# liliumSOC1_sysctrl register map
Vendor: Nordic Semiconductor; Series: liliumSOC1; File version: 1
Registers are 32-bit, read-write, reset 0x0 unless marked. A register's access mark holds for its fields unless they carry their own. Offsets are from the block's base; [hi:lo] are bit positions; lines under a group give offsets from that group; {n}, {i} and the like mark numbered series; 'fields as' and 'values as' point back to an identical list.

## OSCRFR_S — OSCRFR peripheral
Base 0x5F96B000
0x400 STATUS ro
  [0] MODE — Current oscillator mode
    0=Normal mode; 1=Bypass mode
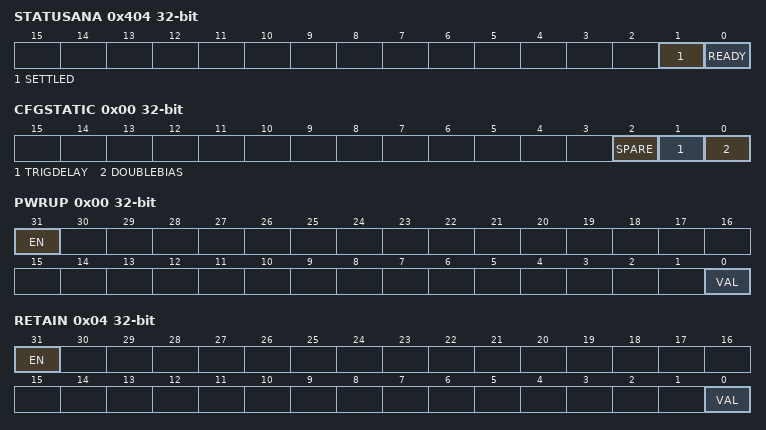
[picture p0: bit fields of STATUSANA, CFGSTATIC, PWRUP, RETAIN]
0x404 STATUSANA ro — Status of analog module output signals
  [1] SETTLED — Current value of the SETTLED signal from the analog module
  [0] READY — Current value of the READY signal from the analog module
0x410 CONFIG group — Unspecified
  0x00 CFGSTATIC — OSCRFR static CFG configuration
    [2] SPARE
    [1] TRIGDELAY — Increase TRIG signal delay
      0=Disabled; 1=Enabled
    [0] DOUBLEBIAS — Enable double bias
      0=Disabled; 1=Enabled
0x440 TRIM group — Unspecified
  0x00 OSC — Oscillation period trimming
    [2:0] VAL — Oscillation period trimming value
      0=Normal trim value; 1=The trim value is 35 percent; 2=The trim value is 154 percent; 3=The trim value is 670 percent; 4=ValNeg51 (The trim value is -54 percent); 5=ValNeg42 (The trim value is -49 percent); 6=ValNeg31 (The trim value is -37 percent); 7=ValNeg18 (The trim value is -26 percent)
  0x04 IBPSR — IBPSR current trimming
    [3:0] VAL — IBPSR current and VREF voltage trimming value
0x480 MIRROR reset 0x1 — Enable LOCK for mirrored registers
  [0] LOCK — Lock for mirrored registers
    0=Disabled (Lock disabled); 1=Enabled (Lock enabled)
0x484 MODE — Oscillator mode
  [1:0] MODE
    0=Automatically handled by the peripheral; 1=Normal mode - Use internal oscillator; 2=Bypass mode - Use OSC_RFR_DIG_AO_0V8 signal
0x500 OVERRIDE group — Unspecified
  0x00 PWRUP — Override the PWRUP signal to the analog module
    [31] EN — Enable the override
      0=Disabled (Override is disabled); 1=Enabled (Override is enabled)
    [0] VAL — Override value for the signal
  0x04 RETAIN — Override the RETAIN signal to the analog module
    fields as OVERRIDE.PWRUP
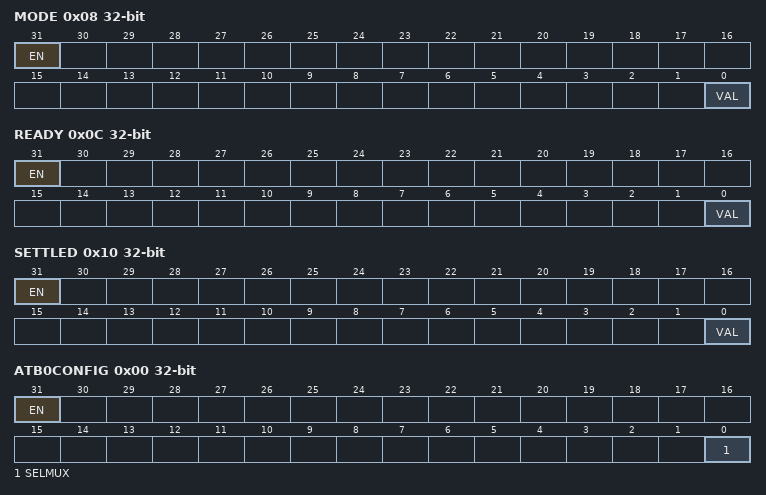
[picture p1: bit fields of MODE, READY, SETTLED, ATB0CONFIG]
  0x08 MODE — Override the MODE signal to the analog module
    fields as OVERRIDE.PWRUP
  0x0C READY — Override the READY signal from the analog module
    [31] EN — Enable the override
      values as OVERRIDE.PWRUP.EN
    [0] VAL — Current value of the signal
  0x10 SETTLED — Override the SETTLED signal from the analog module
    fields as OVERRIDE.READY
0x600 DFT group — Unspecified
  0x00 ATB0CONFIG — Analog Test Bus 0 (ATB0) configuration
    [31] EN — Enable the analog test bus
      0=Disabled (Analog test bus is disabled); 1=Enabled (Analog test bus is enabled)
    [0] SELMUX — Select multiplexer for ATB0
      0=IBPSR4U (IBPSR_4U signal selected); 1=IBPP50N (IBPP_50N signal selected)
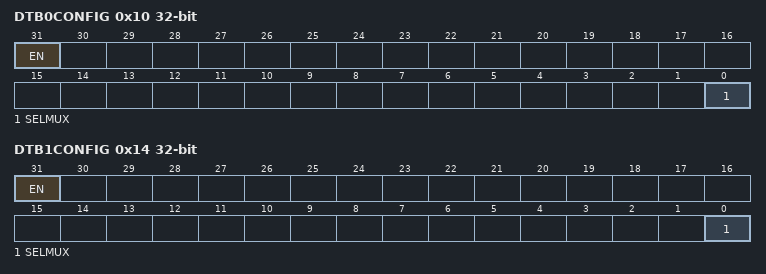
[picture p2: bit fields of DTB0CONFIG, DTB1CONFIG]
  0x10 DTB0CONFIG — Digital Test Bus 0 (DTB0) configuration
    [31] EN — Enable the digital test bus
      0=Disabled (Digital test bus is disabled); 1=Enabled (Digital test bus is enabled)
    [0] SELMUX — Select multiplexer for DTB0
      0=READY (READY signal selected); 1=OSC (OSC_RFR_ANA_AO_0V8 signal selected)
  0x14 DTB1CONFIG — Digital Test Bus 1 (DTB1) configuration
    [31] EN — Enable the digital test bus
      values as DFT.DTB0CONFIG.EN
    [0] SELMUX — Select multiplexer for DTB1
      0=SETTLED (SETTLED signal selected); 1=OSC (OSC_RFR_ANA_AO_0V8 signal selected)
  0x1C DTB3CONFIG — Digital Test Bus 3 (DTB3) configuration
    [27] PWRUPDELTEST — Enable the PWRUP delay test circuit
      0=Disabled (PWRUP delay test circuit is disabled); 1=Enabled (PWRUP delay test circuit is enabled)
  0x30 TCFG — Test mode configuration
    [0] BIASCURRENT — Enable continuous mode for measuring bias current over ATB
      0=Disabled; 1=Enabled

## SWEXT_S — SWEXT peripheral
Base 0x5F96C000
0x400 CONTROL — Switch control for the 1.8V supply to external circuit
  [0] ENABLE — Enable for the switch
    0=Disable (Switch disabled); 1=Enable (Switch enabled)

## VDETIO_S — VDETIO peripheral
Base 0x5F974000
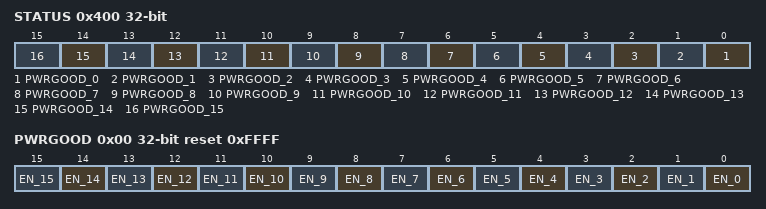
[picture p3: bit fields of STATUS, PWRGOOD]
0x400 STATUS ro — Voltage detector status
  [all] fields
    0=AboveThr (Power good detector detected voltage above threshold level); 1=BelowThr (Power good detector detected voltage below threshold level)
  [n] PWRGOOD_{n} (n=0..15) — Power good detector status for port [{n}]
0x410 CONFIG group — Unspecified
  0x00 PWRGOOD reset 0xFFFF — Power good detector configuration
    [all] fields
      0=Disabled (IO voltage detector is disabled); 1=Enabled (IO voltage detector is enabled)
    [n] EN_{n} (n=0..15) — Enable the power good detector for port [{n}]
